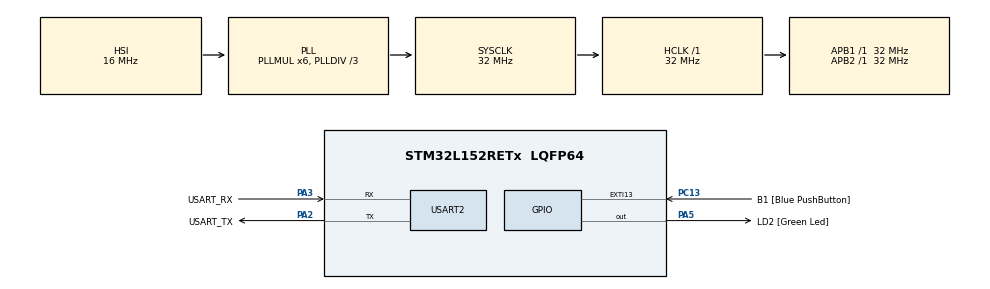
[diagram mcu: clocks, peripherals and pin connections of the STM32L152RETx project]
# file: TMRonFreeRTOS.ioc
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FREERTOS.Tasks01=defaultTask,24,128,StartDefaultTask,Default,NULL,Dynamic,NULL,NULL;THE_TASK,32,128,StartTHE_TASK,Default,NULL,Dynamic,NULL,NULL
FREERTOS.configUSE_NEWLIB_REENTRANT=1
Mcu.Family=STM32L1
Mcu.Name=STM32L152RETx
Mcu.Package=LQFP64
NVIC.PriorityGroup=NVIC_PRIORITYGROUP_4
NVIC.TIM2_IRQn=true\:15\:0\:false\:false\:true\:false\:false\:true\:true
NVIC.TimeBase=TIM2_IRQn
NVIC.TimeBaseIP=TIM2
PA13.GPIO_Label=TMS
PA13.Mode=Serial_Wire
PA13.Signal=SYS_JTMS-SWDIO
PA14.GPIO_Label=TCK
PA14.Mode=Serial_Wire
PA14.Signal=SYS_JTCK-SWCLK
PA2.GPIO_Label=USART_TX
PA2.Mode=Asynchronous
PA2.Signal=USART2_TX
PA3.GPIO_Label=USART_RX
PA3.Mode=Asynchronous
PA3.Signal=USART2_RX
PA5.GPIO_Label=LD2 [Green Led]
PA5.Signal=GPIO_Output
PB3.GPIO_Label=SWO
PB3.Signal=SYS_JTDO-TRACESWO
PC13-WKUP2.GPIO_Label=B1 [Blue PushButton]
PC13-WKUP2.Signal=GPXTI13
PC14-OSC32_IN.Mode=LSE-External-Oscillator
PC14-OSC32_IN.Signal=RCC_OSC32_IN
PC15-OSC32_OUT.Mode=LSE-External-Oscillator
PC15-OSC32_OUT.Signal=RCC_OSC32_OUT
PH0-OSC_IN.Mode=HSE-External-Clock-Source
PH0-OSC_IN.Signal=RCC_OSC_IN
PH1-OSC_OUT.Signal=RCC_OSC_OUT
ProjectManager.HeapSize=0x200
ProjectManager.StackSize=0x400
ProjectManager.TargetToolchain=STM32CubeIDE
RCC.48MHZClocksFreq_Value=48000000
RCC.AHBFreq_Value=32000000
RCC.APB1Freq_Value=32000000
RCC.APB1TimFreq_Value=32000000
RCC.APB2Freq_Value=32000000
RCC.APB2TimFreq_Value=32000000
RCC.HCLKFreq_Value=32000000
RCC.HSE_VALUE=8000000
RCC.HSI_VALUE=16000000
RCC.MSI_VALUE=2097000
RCC.PLLDIV=RCC_PLL_DIV3
RCC.PLLMUL=RCC_PLL_MUL6
RCC.RTCClockSelectionVirtual=RCC_RTCCLKSOURCE_LSE
RCC.SYSCLKFreq_VALUE=32000000
RCC.SYSCLKSource=RCC_SYSCLKSOURCE_PLLCLK
RCC.USBOutput=48000000
RCC.VCOOutputFreq_Value=96000000
USART2.VirtualMode=VM_ASYNC
VP_FREERTOS_VS_CMSIS_V2.Mode=CMSIS_V2
VP_SYS_VS_tim2.Mode=TIM2
board=NUCLEO-L152RE

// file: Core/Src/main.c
/* USER CODE BEGIN Header */
/**
  ******************************************************************************
  * @file           : main.c
  * @brief          : Main program body
  ******************************************************************************
  * @attention
  *
  * Copyright (c) 2024 STMicroelectronics.
  * All rights reserved.
  *
  * This software is licensed under terms that can be found in the LICENSE file
  * in the root directory of this software component.
  * If no LICENSE file comes with this software, it is provided AS-IS.
  *
  ******************************************************************************
  */
/* USER CODE END Header */
#define __DEBUG__
#include "main.h"
#include "cmsis_os.h"

/* USER CODE BEGIN Includes */
#include <stdio.h>
#include <stdlib.h>
#include <string.h>
#include "task.h"
#include "semphr.h"
#include "time.h"
/* USER CODE END Includes */

/* USER CODE BEGIN PD */
#define N_PRIMES 1000
#define REDUNDANT_MODE
#define DELAY 2
/* USER CODE END PD */

UART_HandleTypeDef huart2;

/* Definitions for TheTask */

// Define the task handle
osThreadId_t taskBenchmark;
const osThreadAttr_t taskBenchmarkAttributes = {
  .name = "BenchmarkTask",
  .stack_size = 1000 * 4,
  .priority = (osPriority_t) osPriorityHigh,
};

osThreadId_t taskPrime;
const osThreadAttr_t taskPrimeAttributes = {
  .name = "PrimeTask",
  .stack_size = 2000 * 4,
  .priority = (osPriority_t) osPriorityNormal,
};
#ifndef REDUNDANT_MODE
  osThreadId_t taskPrime1;
  const osThreadAttr_t taskPrimeAttributes1 = {
    .name = "PrimeTask1",
    .stack_size = 2000 * 4,
    .priority = (osPriority_t) osPriorityNormal,
  };
#endif

void SystemClock_Config(void);
static void MX_GPIO_Init(void);
static void MX_USART2_UART_Init(void);

// define the task bodies
void taskBenchmarkBody(void *argument);
void taskPrimeBody(void *argument);
#ifndef REDUNDANT_MODE
  void taskPrimeBody1(void *argument);
#endif

// define the commit functions
void commitPrime();
#ifndef REDUNDANT_MODE
  void commitPrime1(uint16_t * arr);
#endif

//create a semaphore to tell the benchmark task that the prime task is done
SemaphoreHandle_t xSemaphore;
#ifndef REDUNDANT_MODE
  SemaphoreHandle_t xSemaphore1;
#endif

// input struct for prime function
typedef struct inputPrime {
  uint16_t n_primes[N_PRIMES];
  uint16_t index;
  uint16_t n;
} inputPrime_t;

void commitPrime(){
  inputPrime_t * input = (inputPrime_t*) xGetInput();
  if (input->index == N_PRIMES){
    printf("\nPrime numbers: ");
    for(int i = 0; i < N_PRIMES; i+=(N_PRIMES/10)){
      for(int j = i; j < i+(N_PRIMES/10); j++){
        printf("%d ", input->n_primes[j]);
      }
      printf("\n");
    }
    xSemaphoreGive(xSemaphore);
  }
}

void commitPrime1(uint16_t * arr){
	for(int i = 0; i < N_PRIMES; i+=(N_PRIMES/10)){
	    for(int j = i; j < i+(N_PRIMES/10); j++){
	      printf("%d ", arr[j]);
	   }
	  printf("\n");
	}
}

int main(void)
{

  /* MCU Configuration--------------------------------------------------------*/

  /* Reset of all peripherals, Initializes the Flash interface and the Systick. */
  HAL_Init();

  /* Configure the system clock */
  SystemClock_Config();

  /* Initialize all configured peripherals */
  MX_GPIO_Init();
  MX_USART2_UART_Init();

  /* Init scheduler */
  osKernelInitialize();

  /* Create the thread(s) */
  /* creation of TheTask */
  #ifdef REDUNDANT_MODE
    // create the prime task in redundant mode
    taskPrime = osThreadNewRedundant(taskPrimeBody, NULL, &taskPrimeAttributes);

    // initialize the input
    inputPrime_t * inputPrime = pvPortMalloc(sizeof(inputPrime_t));
    inputPrime->index = 0;
    for(int i = 0; i < N_PRIMES; i++){
      inputPrime->n_primes[i] = 0;
    }
    inputPrime->n = 2;
    xSetInput(taskPrime, inputPrime, sizeof(inputPrime_t));
    xSetCommitFunction(taskPrime, commitPrime, NULL);
  #else
    taskPrime = osThreadNew(taskPrimeBody, NULL, &taskPrimeAttributes);
    taskPrime1 = osThreadNew(taskPrimeBody1, NULL, &taskPrimeAttributes1);
  #endif
  taskBenchmark = osThreadNew(taskBenchmarkBody, NULL, &taskBenchmarkAttributes);

  #ifdef __DEBUG__
  	printTaskList();
  #endif

  /* Start scheduler */
  osKernelStart();

  /* We should never get here as control is now taken by the scheduler */
  /* Infinite loop */
  while (1)
  {

  }
}

void SystemClock_Config(void)
{
  RCC_OscInitTypeDef RCC_OscInitStruct = {0};
  RCC_ClkInitTypeDef RCC_ClkInitStruct = {0};

  /** Configure the main internal regulator output voltage
  */
  __HAL_PWR_VOLTAGESCALING_CONFIG(PWR_REGULATOR_VOLTAGE_SCALE1);

  /** Initializes the RCC Oscillators according to the specified parameters
  * in the RCC_OscInitTypeDef structure.
  */
  RCC_OscInitStruct.OscillatorType = RCC_OSCILLATORTYPE_HSI;
  RCC_OscInitStruct.HSIState = RCC_HSI_ON;
  RCC_OscInitStruct.HSICalibrationValue = RCC_HSICALIBRATION_DEFAULT;
  RCC_OscInitStruct.PLL.PLLState = RCC_PLL_ON;
  RCC_OscInitStruct.PLL.PLLSource = RCC_PLLSOURCE_HSI;
  RCC_OscInitStruct.PLL.PLLMUL = RCC_PLL_MUL6;
  RCC_OscInitStruct.PLL.PLLDIV = RCC_PLL_DIV3;
  if (HAL_RCC_OscConfig(&RCC_OscInitStruct) != HAL_OK)
  {
    Error_Handler();
  }

  /** Initializes the CPU, AHB and APB buses clocks
  */
  RCC_ClkInitStruct.ClockType = RCC_CLOCKTYPE_HCLK|RCC_CLOCKTYPE_SYSCLK
                              |RCC_CLOCKTYPE_PCLK1|RCC_CLOCKTYPE_PCLK2;
  RCC_ClkInitStruct.SYSCLKSource = RCC_SYSCLKSOURCE_PLLCLK;
  RCC_ClkInitStruct.AHBCLKDivider = RCC_SYSCLK_DIV1;
  RCC_ClkInitStruct.APB1CLKDivider = RCC_HCLK_DIV1;
  RCC_ClkInitStruct.APB2CLKDivider = RCC_HCLK_DIV1;

  if (HAL_RCC_ClockConfig(&RCC_ClkInitStruct, FLASH_LATENCY_1) != HAL_OK)
  {
    Error_Handler();
  }
}

static void MX_USART2_UART_Init(void)
{

  huart2.Instance = USART2;
  huart2.Init.BaudRate = 115200;
  huart2.Init.WordLength = UART_WORDLENGTH_8B;
  huart2.Init.StopBits = UART_STOPBITS_1;
  huart2.Init.Parity = UART_PARITY_NONE;
  huart2.Init.Mode = UART_MODE_TX_RX;
  huart2.Init.HwFlowCtl = UART_HWCONTROL_NONE;
  huart2.Init.OverSampling = UART_OVERSAMPLING_16;
  if (HAL_UART_Init(&huart2) != HAL_OK)
  {
    Error_Handler();
  }

}

static void MX_GPIO_Init(void)
{
  GPIO_InitTypeDef GPIO_InitStruct = {0};

  /* GPIO Ports Clock Enable */
  __HAL_RCC_GPIOC_CLK_ENABLE();
  __HAL_RCC_GPIOH_CLK_ENABLE();
  __HAL_RCC_GPIOA_CLK_ENABLE();
  __HAL_RCC_GPIOB_CLK_ENABLE();
  __HAL_RCC_GPIOD_CLK_ENABLE();

  /*Configure GPIO pin Output Level */
  HAL_GPIO_WritePin(LD2_GPIO_Port, LD2_Pin, GPIO_PIN_RESET);

  /*Configure GPIO pin : B1_Pin */
  GPIO_InitStruct.Pin = B1_Pin;
  GPIO_InitStruct.Mode = GPIO_MODE_IT_RISING;
  GPIO_InitStruct.Pull = GPIO_NOPULL;
  HAL_GPIO_Init(B1_GPIO_Port, &GPIO_InitStruct);

  /*Configure GPIO pins : PC0 PC1 PC2 PC3
                           PC4 PC5 PC6 PC7
                           PC8 PC9 PC10 PC11
                           PC12 */
  GPIO_InitStruct.Pin = GPIO_PIN_0|GPIO_PIN_1|GPIO_PIN_2|GPIO_PIN_3
                          |GPIO_PIN_4|GPIO_PIN_5|GPIO_PIN_6|GPIO_PIN_7
                          |GPIO_PIN_8|GPIO_PIN_9|GPIO_PIN_10|GPIO_PIN_11
                          |GPIO_PIN_12;
  GPIO_InitStruct.Mode = GPIO_MODE_ANALOG;
  GPIO_InitStruct.Pull = GPIO_NOPULL;
  HAL_GPIO_Init(GPIOC, &GPIO_InitStruct);

  /*Configure GPIO pins : PA0 PA1 PA4 PA6
                           PA7 PA8 PA9 PA10
                           PA11 PA12 PA15 */
  GPIO_InitStruct.Pin = GPIO_PIN_0|GPIO_PIN_1|GPIO_PIN_4|GPIO_PIN_6
                          |GPIO_PIN_7|GPIO_PIN_8|GPIO_PIN_9|GPIO_PIN_10
                          |GPIO_PIN_11|GPIO_PIN_12|GPIO_PIN_15;
  GPIO_InitStruct.Mode = GPIO_MODE_ANALOG;
  GPIO_InitStruct.Pull = GPIO_NOPULL;
  HAL_GPIO_Init(GPIOA, &GPIO_InitStruct);

  /*Configure GPIO pin : LD2_Pin */
  GPIO_InitStruct.Pin = LD2_Pin;
  GPIO_InitStruct.Mode = GPIO_MODE_OUTPUT_PP;
  GPIO_InitStruct.Pull = GPIO_NOPULL;
  GPIO_InitStruct.Speed = GPIO_SPEED_FREQ_LOW;
  HAL_GPIO_Init(LD2_GPIO_Port, &GPIO_InitStruct);

  /*Configure GPIO pins : PB0 PB1 PB2 PB10
                           PB11 PB12 PB13 PB14
                           PB15 PB4 PB5 PB6
                           PB7 PB8 PB9 */
  GPIO_InitStruct.Pin = GPIO_PIN_0|GPIO_PIN_1|GPIO_PIN_2|GPIO_PIN_10
                          |GPIO_PIN_11|GPIO_PIN_12|GPIO_PIN_13|GPIO_PIN_14
                          |GPIO_PIN_15|GPIO_PIN_4|GPIO_PIN_5|GPIO_PIN_6
                          |GPIO_PIN_7|GPIO_PIN_8|GPIO_PIN_9;
  GPIO_InitStruct.Mode = GPIO_MODE_ANALOG;
  GPIO_InitStruct.Pull = GPIO_NOPULL;
  HAL_GPIO_Init(GPIOB, &GPIO_InitStruct);

  /*Configure GPIO pin : PD2 */
  GPIO_InitStruct.Pin = GPIO_PIN_2;
  GPIO_InitStruct.Mode = GPIO_MODE_ANALOG;
  GPIO_InitStruct.Pull = GPIO_NOPULL;
  HAL_GPIO_Init(GPIOD, &GPIO_InitStruct);

}

void taskBenchmarkBody(void *argument)
{
  unsigned long start, end;
  #ifdef REDUNDANT_MODE
    xSemaphore = xSemaphoreCreateBinary();
    xSemaphoreGive(xSemaphore);
    start = xTaskGetTickCount();
    osDelay(10);
    xSemaphoreTake(xSemaphore, portMAX_DELAY);
    end = xTaskGetTickCount();
    printf("Time taken for prime task: %f\n", (double)(end - start)/configTICK_RATE_HZ);
  #else
    xSemaphore = xSemaphoreCreateBinary();
    xSemaphoreGive(xSemaphore);
    xSemaphore1 = xSemaphoreCreateBinary();
    xSemaphoreGive(xSemaphore1);
    start = xTaskGetTickCount();
    osDelay(10);
    xSemaphoreTake(xSemaphore, portMAX_DELAY);
    xSemaphoreTake(xSemaphore1, portMAX_DELAY);
    end = xTaskGetTickCount();
    printf("Time taken for prime task: %f\n", (double)(end - start)/configTICK_RATE_HZ);
  #endif
  vTaskDelete(NULL);
}

void taskPrimeBody(void *argument){
  if(strcmp(pcTaskGetName(NULL), "PrimeTask") == 0){
    xSemaphoreTake(xSemaphore, portMAX_DELAY);
  }
  #ifdef REDUNDANT_MODE
    inputPrime_t * input = (inputPrime_t*) xGetInput();
    while(input->index < N_PRIMES){
      uint8_t is_prime = 1;
      for(int i = 0; i < N_PRIMES && input->n_primes[i] != 0; i++) {
        if(input->n % input->n_primes[i] == 0){
          is_prime = 0;
          break;
        }
      }
      if(is_prime){
        input->n_primes[input->index] = input->n;
        input->index++;
      }
      input->n++;
      osDelay(DELAY);
    }
  #else
    uint16_t n_primes[N_PRIMES];
    uint16_t index = 0;
    uint16_t n = 2;
    for(int i = 0; i < N_PRIMES; i++){
      n_primes[i] = 0;
    }
    while(index < N_PRIMES){
      uint8_t is_prime = 1;
      for(int i = 0; i < N_PRIMES && n_primes[i] != 0; i++) {
        if(n % n_primes[i] == 0){
          is_prime = 0;
          break;
        }
      }
      if(is_prime){
        n_primes[index] = n;
        index++;
      }
      n++;
      osDelay(DELAY);
    }
    xSemaphoreGive(xSemaphore);
  #endif
  vTaskDelete(NULL);
}

#ifndef REDUNDANT_MODE
void taskPrimeBody1(void *argument){
  xSemaphoreTake(xSemaphore1, portMAX_DELAY);
  uint16_t n_primes[N_PRIMES];
    uint16_t index = 0;
    uint16_t n = 2;
    for(int i = 0; i < N_PRIMES; i++){
      n_primes[i] = 0;
    }
    while(index < N_PRIMES){
      uint8_t is_prime = 1;
      for(int i = 0; i < N_PRIMES && n_primes[i] != 0; i++) {
        if(n % n_primes[i] == 0){
          is_prime = 0;
          break;
        }
      }
      if(is_prime){
        n_primes[index] = n;
        index++;
      }
      n++;
      osDelay(DELAY);
    }
    commitPrime1(n_primes);
  xSemaphoreGive(xSemaphore1);
  vTaskDelete(NULL);
}
#endif

void HAL_TIM_PeriodElapsedCallback(TIM_HandleTypeDef *htim)
{
  if (htim->Instance == TIM2) {
    HAL_IncTick();
  }
}

void Error_Handler(void)
{
  __disable_irq();
  while (1)
  {
  }
}
